# STM32U585 register map
File version: 2.2
CPU: CM33 r0p1, little endian, MPU, FPU, 4 interrupt priority bits
Registers are 32-bit, read-write, reset 0x0 unless marked. A register's access mark holds for its fields unless they carry their own. Offsets are from the block's base; [hi:lo] are bit positions; 'fields as' and 'values as' point back to an identical list.

## LPTIM1 — Low power timer
Base 0x46004400
Same registers: LPTIM2 0x40009400, LPTIM3 0x46004800, SEC_LPTIM2 0x50009400, SEC_LPTIM1 0x56004400, SEC_LPTIM3 0x56004800
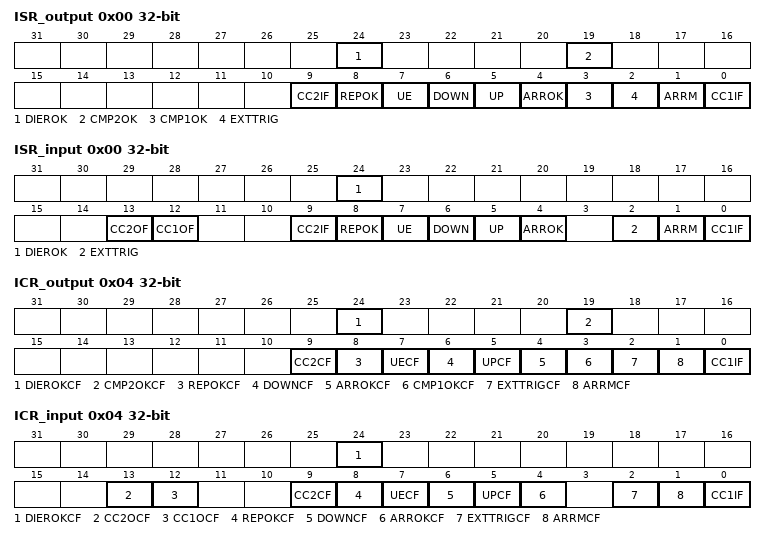
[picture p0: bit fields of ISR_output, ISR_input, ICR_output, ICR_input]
0x00 ISR_output ro — Interrupt and Status Register (output mode)
  [24] DIEROK — Interrupt enable register update OK
  [19] CMP2OK — Compare register 2 update OK
  [9] CC2IF — Compare 2 interrupt flag
  [8] REPOK — Repetition register update
  [7] UE — LPTIM update event
  [6] DOWN — Counter direction change up to
  [5] UP — Counter direction change down to
  [4] ARROK — Autoreload register update
  [3] CMP1OK — Compare register 1 update OK
  [2] EXTTRIG — External trigger edge
  [1] ARRM — Autoreload match
  [0] CC1IF — Compare 1 interrupt flag
0x00 ISR_input ro (alternate view of ISR_output) — Interrupt and Status Register (intput mode)
  [24] DIEROK — Interrupt enable register update OK
  [13] CC2OF — Capture 2 over-capture flag
  [12] CC1OF — Capture 1 over-capture flag
  [9] CC2IF — Capture 2 interrupt flag
  [8] REPOK — Repetition register update
  [7] UE — LPTIM update event
  [6] DOWN — Counter direction change up to
  [5] UP — Counter direction change down to
  [4] ARROK — Autoreload register update
  [2] EXTTRIG — External trigger edge
  [1] ARRM — Autoreload match
  [0] CC1IF — Compare 1 interrupt flag
0x04 ICR_output wo — Interrupt Clear Register (output mode)
  [24] DIEROKCF — Interrupt enable register update OK clear flag
  [19] CMP2OKCF — Compare register 2 update OK clear flag
  [9] CC2CF — Capture/compare 2 clear flag
  [8] REPOKCF — Repetition register update OK clear
  [7] UECF — Update event clear flag
  [6] DOWNCF — Direction change to down Clear
  [5] UPCF — Direction change to UP Clear
  [4] ARROKCF — Autoreload register update OK Clear
  [3] CMP1OKCF — Compare register 1 update OK Clear
  [2] EXTTRIGCF — External trigger valid edge Clear
  [1] ARRMCF — Autoreload match Clear
  [0] CC1IF — Capture/compare 1 clear flag
0x04 ICR_input wo (alternate view of ICR_output) — Interrupt Clear Register (intput mode)
  [24] DIEROKCF — Interrupt enable register update OK clear flag
  [13] CC2OCF — Capture/compare 2 over-capture clear flag
  [12] CC1OCF — Capture/compare 1 over-capture clear flag
  [9] CC2CF — Capture/compare 2 clear flag
  [8] REPOKCF — Repetition register update OK clear
  [7] UECF — Update event clear flag
  [6] DOWNCF — Direction change to down Clear
  [5] UPCF — Direction change to UP Clear
  [4] ARROKCF — Autoreload register update OK Clear
  [2] EXTTRIGCF — External trigger valid edge Clear
  [1] ARRMCF — Autoreload match Clear
  [0] CC1IF — Capture/compare 1 clear flag
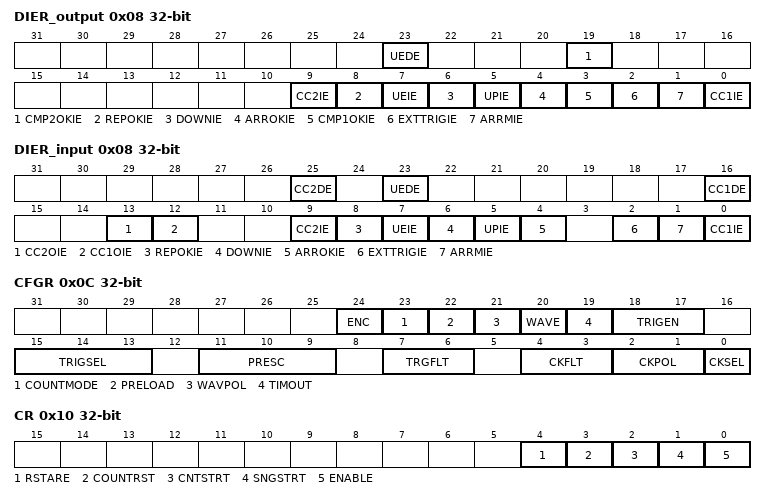
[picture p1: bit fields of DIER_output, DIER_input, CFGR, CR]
0x08 DIER_output — LPTIM interrupt Enable Register (output mode)
  [23] UEDE — Update event DMA request enable
    0=UE DMA request disabled; 1=UE DMA request enabled
  [19] CMP2OKIE — Compare register 2 update OK interrupt enable
    0=CMPOK register 2 interrupt disabled; 1=CMPOK register 2 interrupt enabled
  [9] CC2IE — Capture/compare 2 interrupt enable
    0=Capture/compare 2 interrupt disabled; 1=Capture/compare 2 interrupt enabled
  [8] REPOKIE — Repetition register update OK interrupt Enable
    0=Repetition register update OK interrupt disabled; 1=Repetition register update OK interrupt enabled
  [7] UEIE — Update event interrupt enable
    0=Update event interrupt disabled; 1=Update event interrupt enabled
  [6] DOWNIE — Direction change to down Interrupt Enable
    0=DOWN interrupt disabled; 1=DOWN interrupt enabled
  [5] UPIE — Direction change to UP Interrupt Enable
    0=UP interrupt disabled; 1=UP interrupt enabled
  [4] ARROKIE — Autoreload register update OK Interrupt Enable
    0=ARROK interrupt disabled; 1=ARROK interrupt enabled
  [3] CMP1OKIE — Compare register 1 update OK interrupt enable
    0=CMPOK register 1 interrupt disabled; 1=CMPOK register 1 interrupt enabled
  [2] EXTTRIGIE — External trigger valid edge Interrupt Enable
    0=EXTTRIG interrupt disabled; 1=EXTTRIG interrupt enabled
  [1] ARRMIE — Autoreload match Interrupt Enable
    0=ARRM interrupt disabled; 1=ARRM interrupt enabled
  [0] CC1IE — Capture/compare 1 interrupt enable
    0=Capture/compare 1 interrupt disabled; 1=Capture/compare 1 interrupt enabled
0x08 DIER_input (alternate view of DIER_output) — LPTIM interrupt Enable Register (intput mode)
  [25] CC2DE — Capture/compare 2 DMA request enable
    0=CC2 DMA request disabled; 1=CC2 DMA request enabled
  [23] UEDE — Update event DMA request enable
    0=UE DMA request disabled; 1=UE DMA request enabled
  [16] CC1DE — Capture/compare 1 DMA request enable
    0=CC1 DMA request disabled; 1=CC1 DMA request enabled
  [13] CC2OIE — Capture/compare 2 over-capture interrupt enable
    0=CC2 over-capture interrupt disabled; 1=CC2 over-capture interrupt enabled
  [12] CC1OIE — Capture/compare 1 over-capture interrupt enable
    0=CC1 over-capture interrupt disabled; 1=CC1 over-capture interrupt enabled
  [9] CC2IE — Capture/compare 2 interrupt enable
    values as DIER_output.CC2IE
  [8] REPOKIE — Repetition register update OK interrupt Enable
    values as DIER_output.REPOKIE
  [7] UEIE — Update event interrupt enable
    values as DIER_output.UEIE
  [6] DOWNIE — Direction change to down Interrupt Enable
    0=DOWN interrupt disabled; 1=DOWN interrupt enabled
  [5] UPIE — Direction change to UP Interrupt Enable
    0=UP interrupt disabled; 1=UP interrupt enabled
  [4] ARROKIE — Autoreload register update OK Interrupt Enable
    0=ARROK interrupt disabled; 1=ARROK interrupt enabled
  [2] EXTTRIGIE — External trigger valid edge Interrupt Enable
    0=EXTTRIG interrupt disabled; 1=EXTTRIG interrupt enabled
  [1] ARRMIE — Autoreload match Interrupt Enable
    0=ARRM interrupt disabled; 1=ARRM interrupt enabled
  [0] CC1IE — Capture/compare 1 interrupt enable
    values as DIER_output.CC1IE
0x0C CFGR — Configuration Register
  [24] ENC — Encoder mode enable
  [23] COUNTMODE — counter mode enabled
  [22] PRELOAD — Registers update mode
  [21] WAVPOL — Waveform shape polarity
  [20] WAVE — Waveform shape
  [19] TIMOUT — Timeout enable
  [18:17] TRIGEN — Trigger enable and
  [15:13] TRIGSEL — Trigger selector
  [11:9] PRESC — Clock prescaler
  [7:6] TRGFLT — Configurable digital filter for
  [4:3] CKFLT — Configurable digital filter for external
  [2:1] CKPOL — Clock Polarity
  [0] CKSEL — Clock selector
0x10 CR — Control Register
  [4] RSTARE — Reset after read enable
  [3] COUNTRST — Counter reset
  [2] CNTSTRT — Timer start in continuous
  [1] SNGSTRT — LPTIM start in single mode
  [0] ENABLE — LPTIM Enable
0x14 CCR1 — Compare Register
  [15:0] CCR1 — Capture/compare 1 value
0x18 ARR reset 0x1 — Autoreload Register
  [15:0] ARR — Auto reload value
0x1C CNT ro — Counter Register
  [15:0] CNT — Counter value
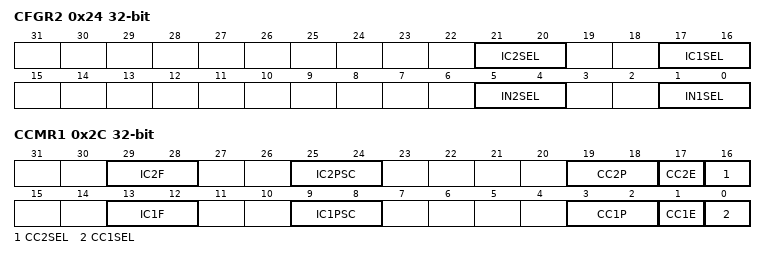
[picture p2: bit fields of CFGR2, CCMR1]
0x24 CFGR2 — LPTIM configuration register 2
  [21:20] IC2SEL — LPTIM input capture 2 selection
  [17:16] IC1SEL — LPTIM input capture 1 selection
  [5:4] IN2SEL — LPTIM input 2 selection
  [1:0] IN1SEL — LPTIM input 1 selection
0x28 RCR — LPTIM repetition register
  [7:0] REP — Repetition register value
0x2C CCMR1 — LPTIM capture/compare mode register 1
  [29:28] IC2F — Input capture 2 filter
  [25:24] IC2PSC — Input capture 2 prescaler
  [19:18] CC2P — Capture/compare 2 output polarity
  [17] CC2E — Capture/compare 2 output enable
  [16] CC2SEL — Capture/compare 2 selection
  [13:12] IC1F — Input capture 1 filter
  [9:8] IC1PSC — Input capture 1 prescaler
  [3:2] CC1P — Capture/compare 1 output polarity
  [1] CC1E — Capture/compare 1 output enable
  [0] CC1SEL — Capture/compare 1 selection
0x34 CCR2 — LPTIM Compare Register 2
  [15:0] CCR2 — Capture/compare 2 value

## LPTIM4 — Low power timer
Base 0x46004C00
Same registers: SEC_LPTIM4 0x56004C00
Registers as LPTIM1, without ISR_output, ISR_input, ICR_output, ICR_input, DIER_output, DIER_input; these are added or differ:
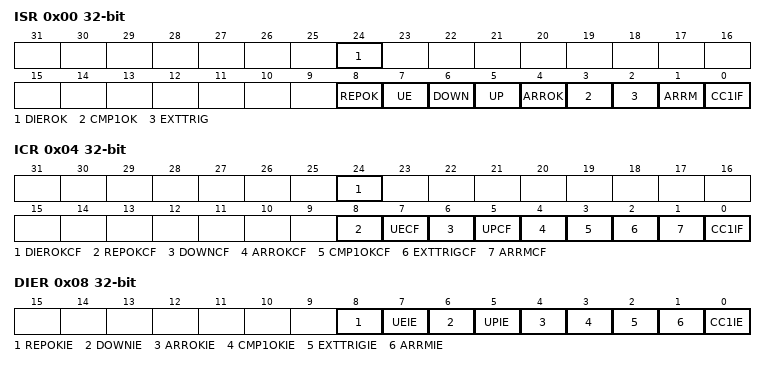
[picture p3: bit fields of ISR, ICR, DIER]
0x00 ISR ro — Interrupt and Status Register
  [24] DIEROK — Interrupt enable register update OK
  [8] REPOK — Repetition register update
  [7] UE — LPTIM update event
  [6] DOWN — Counter direction change up to
  [5] UP — Counter direction change down to
  [4] ARROK — Autoreload register update
  [3] CMP1OK — Compare register 1 update OK
  [2] EXTTRIG — External trigger edge
  [1] ARRM — Autoreload match
  [0] CC1IF — Compare 1 interrupt flag
0x04 ICR wo — Interrupt Clear Register
  [24] DIEROKCF — Interrupt enable register update OK clear flag
  [8] REPOKCF — Repetition register update OK clear
  [7] UECF — Update event clear flag
  [6] DOWNCF — Direction change to down Clear
  [5] UPCF — Direction change to UP Clear
  [4] ARROKCF — Autoreload register update OK Clear
  [3] CMP1OKCF — Compare register 1 update OK Clear
  [2] EXTTRIGCF — External trigger valid edge Clear
  [1] ARRMCF — Autoreload match Clear
  [0] CC1IF — Capture/compare 1 clear flag
0x08 DIER — LPTIM interrupt Enable Register
  [8] REPOKIE
  [7] UEIE — Update event interrupt
  [6] DOWNIE — Direction change to down Interrupt
  [5] UPIE — Direction change to UP Interrupt
  [4] ARROKIE — Autoreload register update OK Interrupt
  [3] CMP1OKIE — Compare register 1 update OK Interrupt
  [2] EXTTRIGIE — External trigger valid edge Interrupt
  [1] ARRMIE — Autoreload match Interrupt
  [0] CC1IE — Capture/compare 1 interrupt enable
    0=Capture/compare 1 interrupt disabled; 1=Capture/compare 1 interrupt enabled
